# mpu register map
Vendor: Texas Instruments
Peripheral module from a debugger description file (folder MSP432).
Registers are 32-bit, access not given, no defined reset value unless marked. A register's access mark holds for its fields unless they carry their own. Offsets are as the file gives them; lines under a group give offsets from that group; [hi:lo] are bit positions; {n}, {i} and the like mark numbered series; 'fields as' and 'values as' point back to an identical list; <NAME> marks a mode.

## MPU
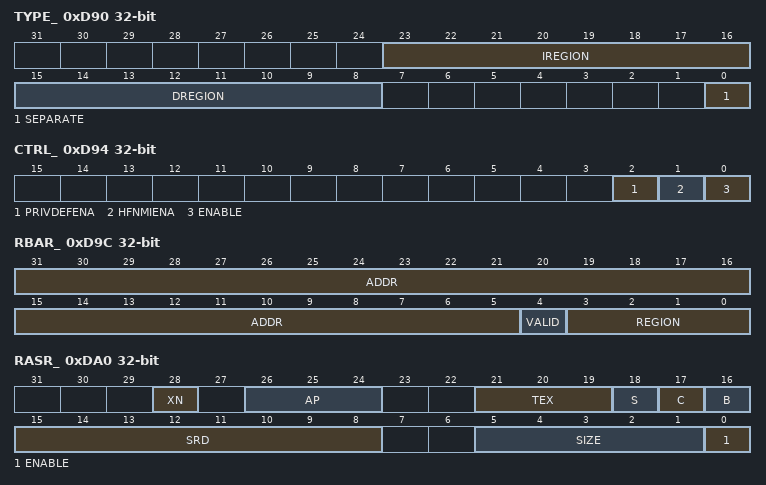
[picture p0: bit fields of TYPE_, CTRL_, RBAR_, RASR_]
0xD90 TYPE_ rw — MPU Type Register
  [23:16] IREGION — Because the processor core uses only a unified MPU, IREGION alw
  [15:8] DREGION — Number of supported MPU regions field
  [0] SEPARATE — Because the processor core uses only a unified MPU, SEPARATE is
0xD94 CTRL_ rw — MPU Control Register
  [2] PRIVDEFENA — This bit enables the default memory map for privileged access,
  [1] HFNMIENA — This bit enables the MPU when in Hard Fault, NMI, and FAULTMASK
  [0] ENABLE — MPU enable bit. Reset clears the ENABLE bit.
    0=ENABLE__0 (disable MPU); 1=ENABLE__1 (enable MPU)
0xD98 RNR_ rw — MPU Region Number Register
  [7:0] REGION — Region select field
0xD9C RBAR_ rw — MPU Region Base Address Register
  [31:5] ADDR — Region base address field
  [4] VALID — MPU Region Number valid bit.
    0=VALID__0 (MPU Region Number Register remains unchanged and is interpreted.); 1=VALID__1 (MPU Region Number Register is overwritten by bits 3:0 (the REGI)
  [3:0] REGION — MPU region override field.
0xDA0 RASR_ rw — MPU Region Attribute and Size Register
  [28] XN — Instruction access disable bit
    0=XN__0 (enable instruction fetches); 1=XN__1 (disable instruction fetches)
  [26:24] AP — Data access permission field
    0=AP__0 (Priviliged permissions: No access. User permissions: No access.); 1=AP__1 (Priviliged permissions: Read-write. User permissions: No access.); 2=AP__2 (Priviliged permissions: Read-write. User permissions: Read-only.); 3=AP__3 (Priviliged permissions: Read-write); 5=AP__5 (Priviliged permissions: Read-only. User permissions: No access.); 6=AP__6 (Priviliged permissions: Read-only. User permissions: Read-only.); 7=AP__7 (Priviliged permissions: Read-only. User permissions: Read-only.)
  [21:19] TEX — Type extension field
  [18] S — Shareable bit
    0=S__0 (not shareable); 1=S__1 (shareable)
  [17] C — Cacheable bit
    0=C__0 (not cacheable); 1=C__1 (cacheable)
  [16] B — Bufferable bit
    0=B__0 (not bufferable); 1=B__1 (bufferable)
  [15:8] SRD — Sub-Region Disable (SRD) field
  [5:1] SIZE — MPU Protection Region Size Field.
    0=SIZE__0 (4KB); 1=SIZE__1 (256MB); 4=SIZE__4 (32B); 5=SIZE__5 (64B); 6=SIZE__6 (128B); 7=SIZE__7 (256B); 8=SIZE__8 (512B); 9=SIZE__9 (1KB); 10=SIZE__10 (2KB); 12=SIZE__12 (8KB); 13=SIZE__13 (16KB); 14=SIZE__14 (32KB); 15=SIZE__15 (64KB); 16=SIZE__16 (128KB); 17=SIZE__17 (256KB); 18=SIZE__18 (512KB); 19=SIZE__19 (1MB); 20=SIZE__20 (2MB); 21=SIZE__21 (4MB); 22=SIZE__22 (8MB); 23=SIZE__23 (16MB); 24=SIZE__24 (32MB); 25=SIZE__25 (64MB); 26=SIZE__26 (128MB); 28=SIZE__28 (512MB); 29=SIZE__29 (1GB); 30=SIZE__30 (2GB); 31=SIZE__31 (4GB)
  [0] ENABLE — Region enable bit.
{0xD9C+8i} RBAR_A{i}_ (i=1..3) — MPU Alias {i} Region Base Address register
{0xDA0+8i} RASR_A{i}_ (i=1..3) — MPU Alias {i} Region Attribute and Size register
